VERSION ""

NS_ :

BS_:

BU_: XXX RADAR SDSU

CM_ "Ocelot smartDSU bridge status TX (firmware-derived from RetroPilot/ocelot main.c TIM3_IRQ_Handler)"
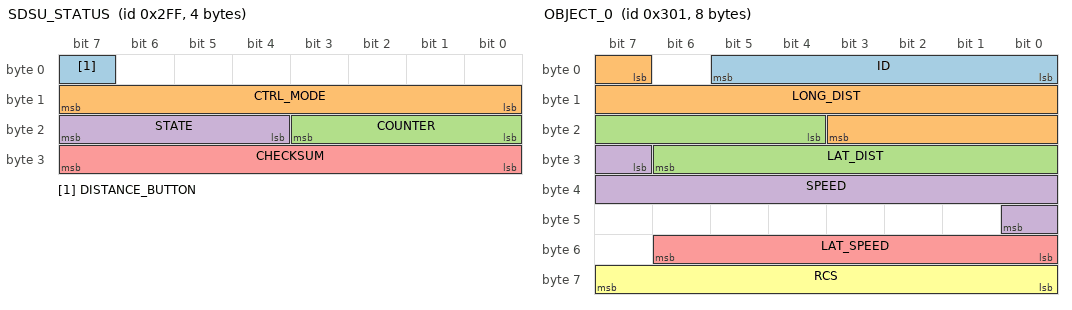
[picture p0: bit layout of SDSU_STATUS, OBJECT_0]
BO_ 767 SDSU_STATUS: 4 SDSU
 SG_ DISTANCE_BUTTON : 7|1@1+ (1,0) [0|1] "" XXX
 SG_ CTRL_MODE : 8|8@1+ (1,0) [0|255] "" XXX
 SG_ COUNTER : 16|4@1+ (1,0) [0|15] "" XXX
 SG_ STATE : 20|4@1+ (1,0) [0|15] "" XXX
 SG_ CHECKSUM : 24|8@1+ (1,0) [0|255] "" XXX

BO_ 768 BUTTONS: 8 RADAR
 SG_ LKAS_PRESS : 2|1@0+ (1,0) [0|1] "" XXX
 SG_ DISTANCE_PRESS : 5|1@0+ (1,0) [0|1] "" XXX

BO_ 769 OBJECT_0: 8 RADAR
 SG_ ID : 5|6@0+ (1,0) [0|255] "" XXX
 SG_ LONG_DIST : 7|13@1+ (0.03,0) [0|65535] "m" XXX
 SG_ LAT_DIST : 20|11@1- (0.018,0) [0|15] "" XXX
 SG_ SPEED : 31|10@1- (0.06944444444,0) [0|71] "m/s" XXX
 SG_ LAT_SPEED : 48|7@1- (0.1,0) [0|127] "m/s" XXX
 SG_ RCS : 63|8@0+ (1,0) [0|255] "" XXX

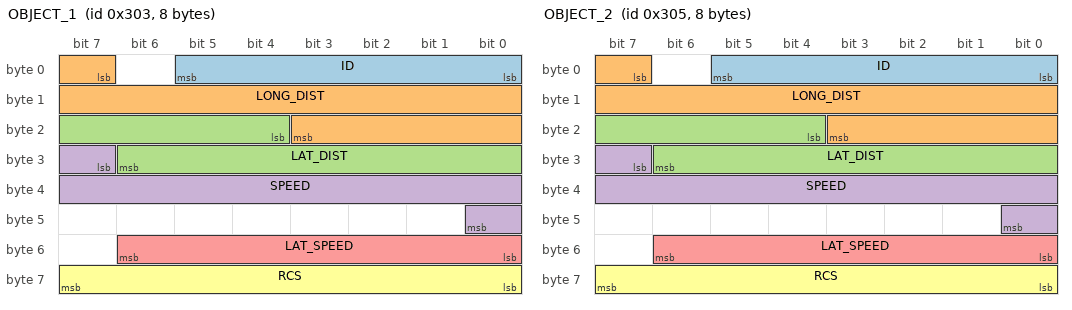
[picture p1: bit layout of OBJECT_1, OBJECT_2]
BO_ 771 OBJECT_1: 8 RADAR
 SG_ ID : 5|6@0+ (1,0) [0|255] "" XXX
 SG_ LONG_DIST : 7|13@1+ (0.03,0) [0|65535] "m" XXX
 SG_ LAT_DIST : 20|11@1- (0.018,0) [0|15] "" XXX
 SG_ SPEED : 31|10@1- (0.06944444444,0) [0|71] "m/s" XXX
 SG_ LAT_SPEED : 48|7@1- (0.1,0) [0|127] "m/s" XXX
 SG_ RCS : 63|8@0+ (1,0) [0|255] "" XXX

BO_ 773 OBJECT_2: 8 RADAR
 SG_ ID : 5|6@0+ (1,0) [0|255] "" XXX
 SG_ LONG_DIST : 7|13@1+ (0.03,0) [0|65535] "m" XXX
 SG_ LAT_DIST : 20|11@1- (0.018,0) [0|15] "" XXX
 SG_ SPEED : 31|10@1- (0.06944444444,0) [0|71] "m/s" XXX
 SG_ LAT_SPEED : 48|7@1- (0.1,0) [0|127] "m/s" XXX
 SG_ RCS : 63|8@0+ (1,0) [0|255] "" XXX

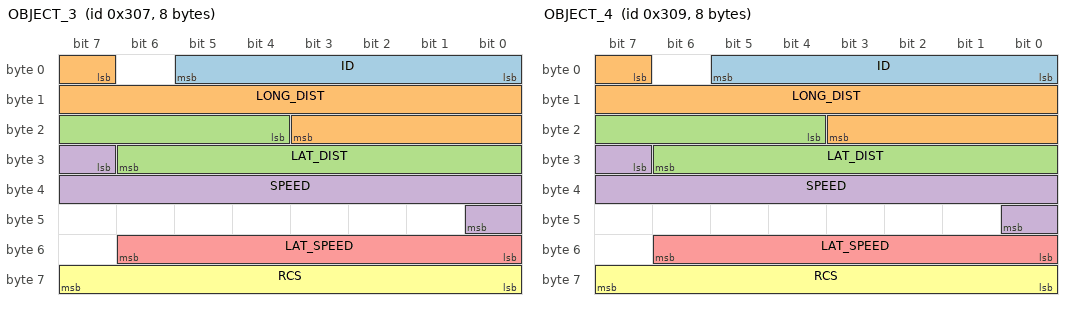
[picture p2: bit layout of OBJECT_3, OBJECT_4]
BO_ 775 OBJECT_3: 8 RADAR
 SG_ ID : 5|6@0+ (1,0) [0|255] "" XXX
 SG_ LONG_DIST : 7|13@1+ (0.03,0) [0|65535] "m" XXX
 SG_ LAT_DIST : 20|11@1- (0.018,0) [0|15] "" XXX
 SG_ SPEED : 31|10@1- (0.06944444444,0) [0|71] "m/s" XXX
 SG_ LAT_SPEED : 48|7@1- (0.1,0) [0|127] "m/s" XXX
 SG_ RCS : 63|8@0+ (1,0) [0|255] "" XXX

BO_ 777 OBJECT_4: 8 RADAR
 SG_ ID : 5|6@0+ (1,0) [0|255] "" XXX
 SG_ LONG_DIST : 7|13@1+ (0.03,0) [0|65535] "m" XXX
 SG_ LAT_DIST : 20|11@1- (0.018,0) [0|15] "" XXX
 SG_ SPEED : 31|10@1- (0.06944444444,0) [0|71] "m/s" XXX
 SG_ LAT_SPEED : 48|7@1- (0.1,0) [0|127] "m/s" XXX
 SG_ RCS : 63|8@0+ (1,0) [0|255] "" XXX

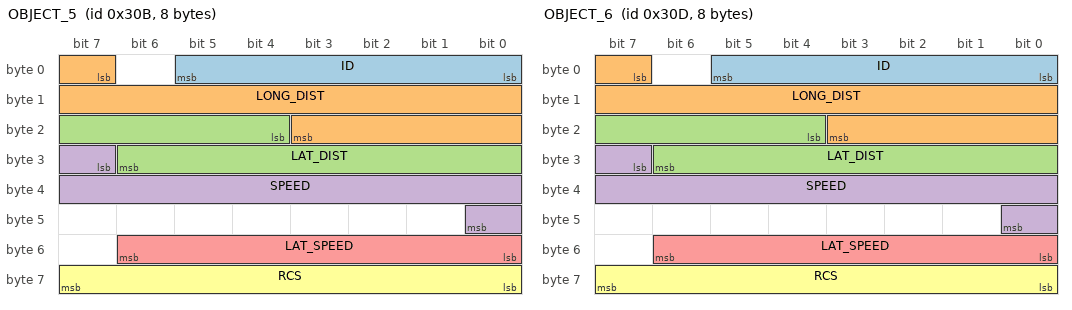
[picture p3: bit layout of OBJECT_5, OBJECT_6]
BO_ 779 OBJECT_5: 8 RADAR
 SG_ ID : 5|6@0+ (1,0) [0|255] "" XXX
 SG_ LONG_DIST : 7|13@1+ (0.03,0) [0|65535] "m" XXX
 SG_ LAT_DIST : 20|11@1- (0.018,0) [0|15] "" XXX
 SG_ SPEED : 31|10@1- (0.06944444444,0) [0|71] "m/s" XXX
 SG_ LAT_SPEED : 48|7@1- (0.1,0) [0|127] "m/s" XXX
 SG_ RCS : 63|8@0+ (1,0) [0|255] "" XXX

BO_ 781 OBJECT_6: 8 RADAR
 SG_ ID : 5|6@0+ (1,0) [0|255] "" XXX
 SG_ LONG_DIST : 7|13@1+ (0.03,0) [0|65535] "m" XXX
 SG_ LAT_DIST : 20|11@1- (0.018,0) [0|15] "" XXX
 SG_ SPEED : 31|10@1- (0.06944444444,0) [0|71] "m/s" XXX
 SG_ LAT_SPEED : 48|7@1- (0.1,0) [0|127] "m/s" XXX
 SG_ RCS : 63|8@0+ (1,0) [0|255] "" XXX

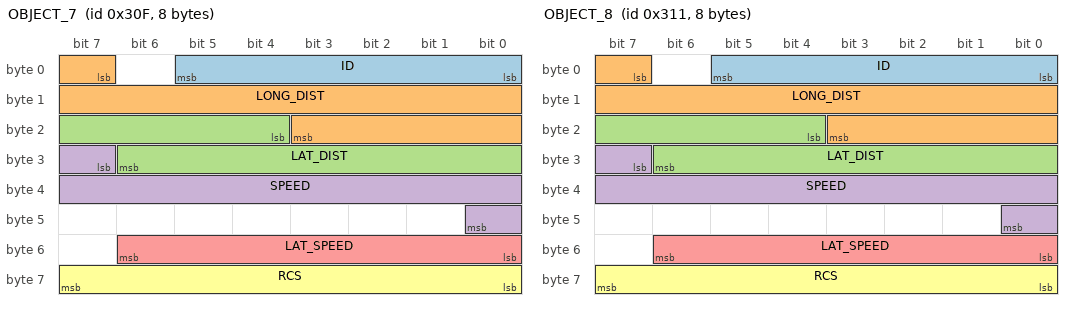
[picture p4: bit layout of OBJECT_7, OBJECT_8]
BO_ 783 OBJECT_7: 8 RADAR
 SG_ ID : 5|6@0+ (1,0) [0|255] "" XXX
 SG_ LONG_DIST : 7|13@1+ (0.03,0) [0|65535] "m" XXX
 SG_ LAT_DIST : 20|11@1- (0.018,0) [0|15] "" XXX
 SG_ SPEED : 31|10@1- (0.06944444444,0) [0|71] "m/s" XXX
 SG_ LAT_SPEED : 48|7@1- (0.1,0) [0|127] "m/s" XXX
 SG_ RCS : 63|8@0+ (1,0) [0|255] "" XXX

BO_ 785 OBJECT_8: 8 RADAR
 SG_ ID : 5|6@0+ (1,0) [0|255] "" XXX
 SG_ LONG_DIST : 7|13@1+ (0.03,0) [0|65535] "m" XXX
 SG_ LAT_DIST : 20|11@1- (0.018,0) [0|15] "" XXX
 SG_ SPEED : 31|10@1- (0.06944444444,0) [0|71] "m/s" XXX
 SG_ LAT_SPEED : 48|7@1- (0.1,0) [0|127] "m/s" XXX
 SG_ RCS : 63|8@0+ (1,0) [0|255] "" XXX

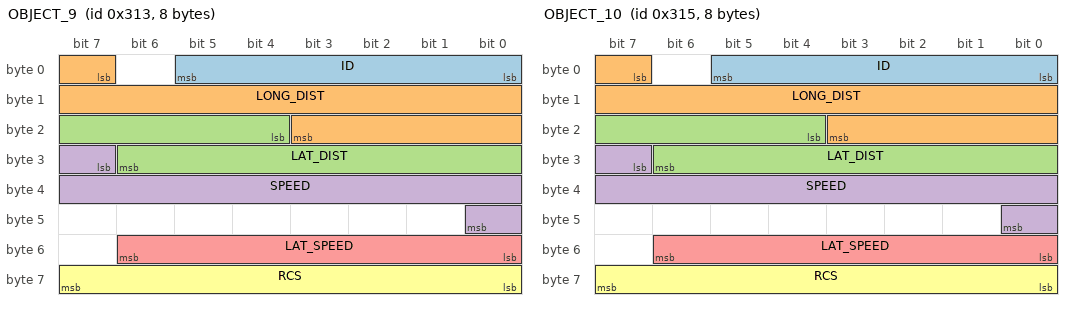
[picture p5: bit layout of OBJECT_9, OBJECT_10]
BO_ 787 OBJECT_9: 8 RADAR
 SG_ ID : 5|6@0+ (1,0) [0|255] "" XXX
 SG_ LONG_DIST : 7|13@1+ (0.03,0) [0|65535] "m" XXX
 SG_ LAT_DIST : 20|11@1- (0.018,0) [0|15] "" XXX
 SG_ SPEED : 31|10@1- (0.06944444444,0) [0|71] "m/s" XXX
 SG_ LAT_SPEED : 48|7@1- (0.1,0) [0|127] "m/s" XXX
 SG_ RCS : 63|8@0+ (1,0) [0|255] "" XXX

BO_ 789 OBJECT_10: 8 RADAR
 SG_ ID : 5|6@0+ (1,0) [0|255] "" XXX
 SG_ LONG_DIST : 7|13@1+ (0.03,0) [0|65535] "m" XXX
 SG_ LAT_DIST : 20|11@1- (0.018,0) [0|15] "" XXX
 SG_ SPEED : 31|10@1- (0.06944444444,0) [0|71] "m/s" XXX
 SG_ LAT_SPEED : 48|7@1- (0.1,0) [0|127] "m/s" XXX
 SG_ RCS : 63|8@0+ (1,0) [0|255] "" XXX

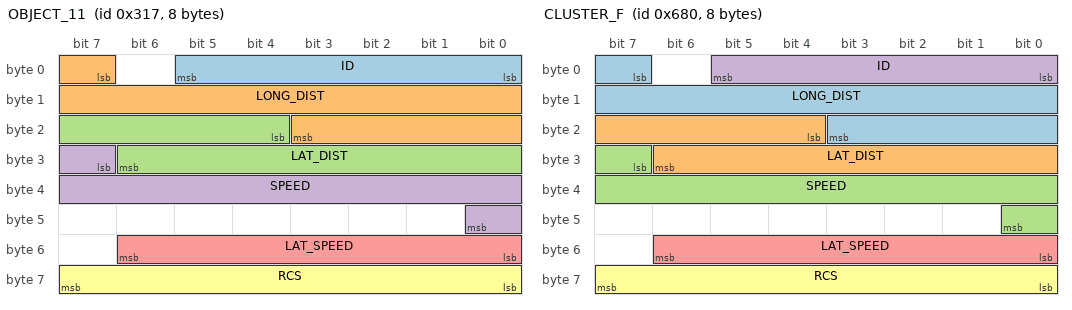
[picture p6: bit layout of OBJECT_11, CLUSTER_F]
BO_ 791 OBJECT_11: 8 RADAR
 SG_ ID : 5|6@0+ (1,0) [0|255] "" XXX
 SG_ LONG_DIST : 7|13@1+ (0.03,0) [0|65535] "m" XXX
 SG_ LAT_DIST : 20|11@1- (0.018,0) [0|15] "" XXX
 SG_ SPEED : 31|10@1- (0.06944444444,0) [0|71] "m/s" XXX
 SG_ LAT_SPEED : 48|7@1- (0.1,0) [0|127] "m/s" XXX
 SG_ RCS : 63|8@0+ (1,0) [0|255] "" XXX

CM_ "Front target"
BO_ 1664 CLUSTER_F: 8 RADAR
 SG_ LONG_DIST : 7|13@1+ (0.03,0) [0|255] "m" XXX
 SG_ LAT_DIST : 20|11@1- (0.015,0) [-20|20] "m" XXX
 SG_ SPEED : 31|10@1- (0.06944444444,0) [0|71] "m/s" XXX
 SG_ ID : 0|6@1+ (1,0) [0|63] "" XXX
 SG_ LAT_SPEED : 48|7@1- (0.1,0) [0|127] "m/s" XXX
 SG_ RCS : 63|8@0+ (1,0) [0|255] "" XXX

CM_ "Front target ahead"
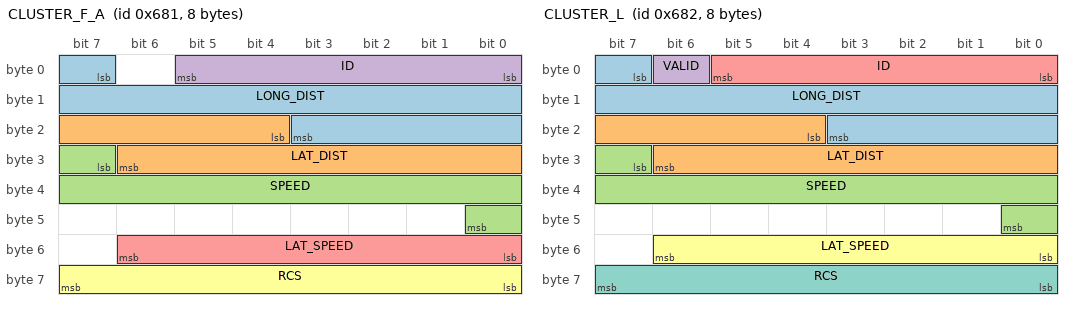
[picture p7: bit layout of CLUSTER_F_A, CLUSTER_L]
BO_ 1665 CLUSTER_F_A: 8 RADAR
 SG_ LONG_DIST : 7|13@1+ (0.03,0) [0|255] "m" XXX
 SG_ LAT_DIST : 20|11@1- (0.015,0) [-20|20] "m" XXX
 SG_ SPEED : 31|10@1- (0.06944444444,0) [0|71] "m/s" XXX
 SG_ ID : 0|6@1+ (1,0) [0|63] "" XXX
 SG_ LAT_SPEED : 48|7@1- (0.1,0) [0|127] "m/s" XXX
 SG_ RCS : 63|8@0+ (1,0) [0|255] "" XXX

CM_ "Left target"
BO_ 1666 CLUSTER_L: 8 RADAR
 SG_ LONG_DIST : 7|13@1+ (0.03,0) [0|255] "m" XXX
 SG_ LAT_DIST : 20|11@1- (0.015,0) [-20|20] "m" XXX
 SG_ SPEED : 31|10@1- (0.06944444444,0) [0|71] "m/s" XXX
 SG_ VALID : 6|1@0+ (1,0) [0|1] "" XXX
 SG_ ID : 0|6@1+ (1,0) [0|63] "" XXX
 SG_ LAT_SPEED : 48|7@1- (0.1,0) [0|127] "m/s" XXX
 SG_ RCS : 63|8@0+ (1,0) [0|255] "" XXX

CM_ "Right target"
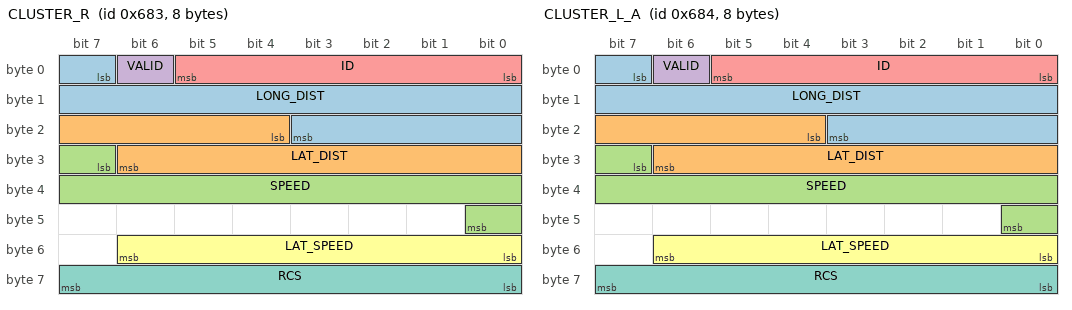
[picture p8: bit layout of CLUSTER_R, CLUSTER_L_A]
BO_ 1667 CLUSTER_R: 8 RADAR
 SG_ LONG_DIST : 7|13@1+ (0.03,0) [0|255] "m" XXX
 SG_ LAT_DIST : 20|11@1- (0.015,0) [-20|20] "m" XXX
 SG_ SPEED : 31|10@1- (0.06944444444,0) [0|71] "m/s" XXX
 SG_ VALID : 6|1@0+ (1,0) [0|1] "" XXX
 SG_ ID : 0|6@1+ (1,0) [0|63] "" XXX
 SG_ LAT_SPEED : 48|7@1- (0.1,0) [0|127] "m/s" XXX
 SG_ RCS : 63|8@0+ (1,0) [0|255] "" XXX

CM_ "Left target ahead"
BO_ 1668 CLUSTER_L_A: 8 RADAR
 SG_ LONG_DIST : 7|13@1+ (0.03,0) [0|255] "m" XXX
 SG_ LAT_DIST : 20|11@1- (0.015,0) [-20|20] "m" XXX
 SG_ SPEED : 31|10@1- (0.06944444444,0) [0|71] "m/s" XXX
 SG_ VALID : 6|1@0+ (1,0) [0|1] "" XXX
 SG_ ID : 0|6@1+ (1,0) [0|63] "" XXX
 SG_ LAT_SPEED : 48|7@1- (0.1,0) [0|127] "m/s" XXX
 SG_ RCS : 63|8@0+ (1,0) [0|255] "" XXX

CM_ "Right target ahead"
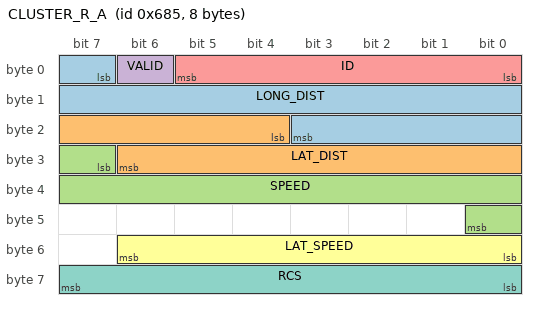
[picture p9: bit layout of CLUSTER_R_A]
BO_ 1669 CLUSTER_R_A: 8 RADAR
 SG_ LONG_DIST : 7|13@1+ (0.03,0) [0|255] "m" XXX
 SG_ LAT_DIST : 20|11@1- (0.015,0) [-20|20] "m" XXX
 SG_ SPEED : 31|10@1- (0.06944444444,0) [0|71] "m/s" XXX
 SG_ VALID : 6|1@0+ (1,0) [0|1] "" XXX
 SG_ ID : 0|6@1+ (1,0) [0|63] "" XXX
 SG_ LAT_SPEED : 48|7@1- (0.1,0) [0|127] "m/s" XXX
 SG_ RCS : 63|8@0+ (1,0) [0|255] "" XXX

VAL_ 767 STATE 0 "NO_FAULT" 1 "FAULT_BAD_CHECKSUM" 2 "FAULT_SEND" 3 "FAULT_SCE" 4 "FAULT_STARTUP" 5 "FAULT_TIMEOUT" 6 "FAULT_INVALID" 7 "STATE_AEB_CTRL" ;

CM_ BO_ 291 "RADAR_HEARTBEAT: Continental ARS (bus 1) liveness frame, 7-byte static payload. Confidence: HIGH (always 00 00 00 00 00 00 2b across 600+ msgs driving + 600+ stationary). Reference: 2026-05-16 RE on route 00000312.";
BO_ 291 RADAR_HEARTBEAT: 7 RADAR
 SG_ STATIC_PAYLOAD : 48|8@1+ (1,0) [0|255] "" XXX

CM_ BO_ 849 "RADAR_STATUS: Continental ARS (bus 1) per-frame status + counter + CRC. Confidence: HIGH structural (B1 counter sig, B6+B7 CRC sig). LOW byte-level for B0/B5 (best-fit only). STATUS_BIT_0..15 are placeholder names for B3+B4 sparse status flags — meanings TBD via fault-injection drives (cover radar, drive multipath, etc.). Reference: 2026-05-16 RE on route 00000312 segs 0-3, Gemini Pro Preview cold handoff. Tesla PR #3011 vocabulary applies once bit→flag mapping is known.";
BO_ 849 RADAR_STATUS: 8 RADAR
 SG_ ProcessorTime : 0|8@1+ (1,0) [0|255] "" XXX
 SG_ MessageCounter : 8|8@1+ (1,0) [0|255] "" XXX
 SG_ STATUS_BIT_0 : 24|1@1+ (1,0) [0|1] "" XXX
 SG_ STATUS_BIT_1 : 25|1@1+ (1,0) [0|1] "" XXX
 SG_ STATUS_BIT_2 : 26|1@1+ (1,0) [0|1] "" XXX
 SG_ STATUS_BIT_3 : 27|1@1+ (1,0) [0|1] "" XXX
 SG_ STATUS_BIT_4 : 28|1@1+ (1,0) [0|1] "" XXX
 SG_ STATUS_BIT_5 : 29|1@1+ (1,0) [0|1] "" XXX
 SG_ STATUS_BIT_6 : 30|1@1+ (1,0) [0|1] "" XXX
 SG_ STATUS_BIT_7 : 31|1@1+ (1,0) [0|1] "" XXX
 SG_ STATUS_BIT_8 : 32|1@1+ (1,0) [0|1] "" XXX
 SG_ STATUS_BIT_9 : 33|1@1+ (1,0) [0|1] "" XXX
 SG_ STATUS_BIT_10 : 34|1@1+ (1,0) [0|1] "" XXX
 SG_ STATUS_BIT_11 : 35|1@1+ (1,0) [0|1] "" XXX
 SG_ STATUS_BIT_12 : 36|1@1+ (1,0) [0|1] "" XXX
 SG_ STATUS_BIT_13 : 37|1@1+ (1,0) [0|1] "" XXX
 SG_ STATUS_BIT_14 : 38|1@1+ (1,0) [0|1] "" XXX
 SG_ STATUS_BIT_15 : 39|1@1+ (1,0) [0|1] "" XXX
 SG_ LoopCounter : 44|4@1+ (1,0) [0|15] "" XXX
 SG_ Checksum : 48|16@1+ (1,0) [0|65535] "" XXX
